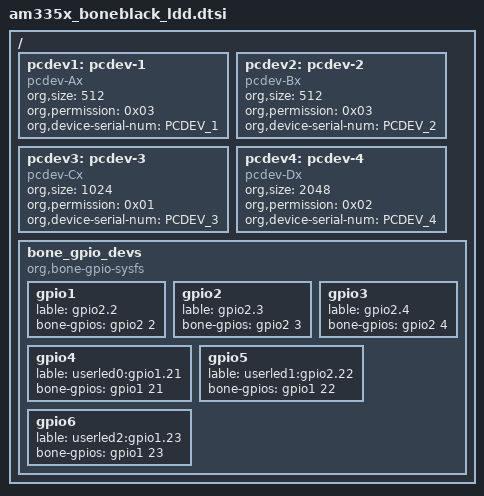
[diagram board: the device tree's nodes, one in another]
/ {
    pcdev1: pcdev-1 {
        compatible = "pcdev-Ax";
        org,size = <512>;
        org,permission = <0x03>;
        org,device-serial-num = "PCDEV_1";
    };

    pcdev2: pcdev-2 {
        compatible = "pcdev-Bx";
        org,size = <512>;
        org,permission = <0x03>;
        org,device-serial-num = "PCDEV_2";
    };

    pcdev3: pcdev-3 {
        compatible = "pcdev-Cx";
        org,size = <1024>;
        org,permission = <0x01>;
        org,device-serial-num = "PCDEV_3";
    };

    pcdev4: pcdev-4 {
        compatible = "pcdev-Dx";
        org,size = <2048>;
        org,permission = <0x02>;
        org,device-serial-num = "PCDEV_4";
    };

    bone_gpio_devs {
        compatible = "org,bone-gpio-sysfs";

        gpio1 {
            lable = "gpio2.2";
            bone-gpios = <&gpio2 2 GPIO_ACTIVE_HIGH>;
        };

        gpio2 {
            lable = "gpio2.3";
            bone-gpios = <&gpio2 3 GPIO_ACTIVE_HIGH>;
        };

        gpio3 {
            lable = "gpio2.4";
            bone-gpios = <&gpio2 4 GPIO_ACTIVE_HIGH>;
        };

        gpio4 {
            lable = "userled0:gpio1.21";
            bone-gpios = <&gpio1 21 GPIO_ACTIVE_HIGH>;
        };

        gpio5 {
            lable = "userled1:gpio2.22";
            bone-gpios = <&gpio1 22 GPIO_ACTIVE_HIGH>;
        };

        gpio6 {
            lable = "userled2:gpio1.23";
            bone-gpios = <&gpio1 23 GPIO_ACTIVE_HIGH>;
        };
    };
};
